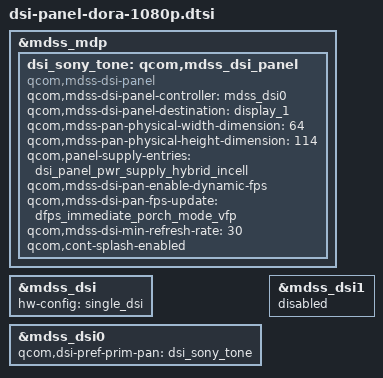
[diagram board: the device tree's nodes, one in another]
/* Copyright (c) 2014-2015, The Linux Foundation. All rights reserved.
 *
 * This program is free software; you can redistribute it and/or modify
 * it under the terms of the GNU General Public License version 2 and
 * only version 2 as published by the Free Software Foundation.
 *
 * This program is distributed in the hope that it will be useful,
 * but WITHOUT ANY WARRANTY; without even the implied warranty of
 * MERCHANTABILITY or FITNESS FOR A PARTICULAR PURPOSE.  See the
 * GNU General Public License for more details.
 */

#include "dsi-panel-synaptics-jdi-1080p-cmd.dtsi"
#include "dsi-panel-synaptics-lgd-1080p-cmd.dtsi"
#include "dsi-panel-synaptics-auo-1080p-cmd.dtsi"
#include "dsi-panel-synaptics-sharp-1080p-cmd.dtsi"
#include "dsi-panel-novatek-lgd-1080p-video.dtsi"
#include "dsi-panel-default.dtsi"

&mdss_mdp {
	dsi_sony_tone: qcom,mdss_dsi_panel {
		compatible = "qcom,mdss-dsi-panel";
		status = "ok";
		qcom,mdss-dsi-panel-controller = <&mdss_dsi0>;
		qcom,mdss-dsi-panel-destination = "display_1";
		qcom,mdss-pan-physical-width-dimension = <64>;
		qcom,mdss-pan-physical-height-dimension = <114>;
		qcom,panel-supply-entries = <&dsi_panel_pwr_supply>;
		qcom,mdss-dsi-pan-enable-dynamic-fps;
		qcom,mdss-dsi-pan-fps-update = "dfps_immediate_porch_mode_vfp";
		qcom,mdss-dsi-min-refresh-rate = <30>;
	};
};

&dsi_sony_tone {
	qcom,cont-splash-enabled;
	qcom,panel-supply-entries = <&dsi_panel_pwr_supply_hybrid_incell>;
};

&mdss_dsi {
	hw-config = "single_dsi";
};

&mdss_dsi0 {
        qcom,dsi-pref-prim-pan = <&dsi_sony_tone>;
};

&mdss_dsi1 {
        status = "disabled";
};

